# f28p551x_periph_ac_regs register map
Vendor: Texas Instruments
Peripheral module from a debugger description file (folder C2000).
Address unit: 16 bits
Registers are 32-bit, read-write, no defined reset value unless marked. A register's access mark holds for its fields unless they carry their own. Offsets are as the file gives them; lines under a group give offsets from that group; [hi:lo] are bit positions; {n}, {i} and the like mark numbered series; 'fields as' and 'values as' point back to an identical list; <NAME> marks a mode.

## PERIPH_AC_REGS — PERIPH AC Registers
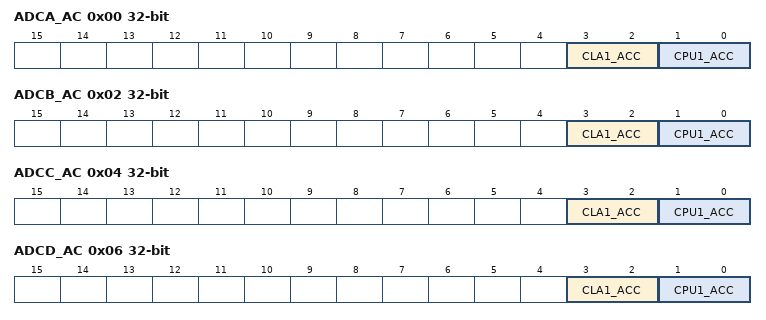
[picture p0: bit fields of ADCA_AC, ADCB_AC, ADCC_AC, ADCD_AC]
0x00 ADCA_AC — ADCA Controller Access Control Register
  [3:2] CLA1_ACC — CLA1 Access Conditions to Peripheral
  [1:0] CPU1_ACC — CPU1 Access conditions to peripheral
0x02 ADCB_AC — ADCB Controller Access Control Register
  fields as ADCA_AC
0x04 ADCC_AC — ADCC Controller Access Control Register
  fields as ADCA_AC
0x06 ADCD_AC — ADCD Controller Access Control Register
  fields as ADCA_AC
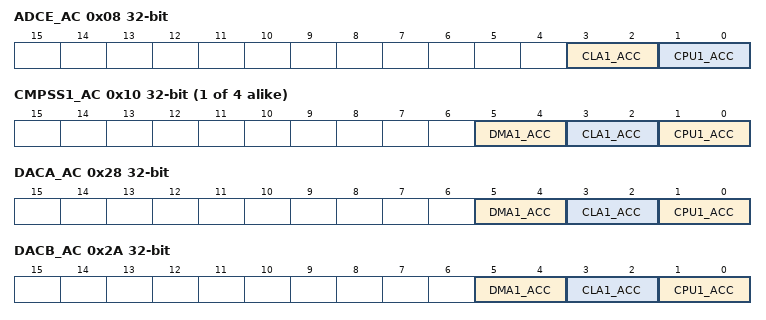
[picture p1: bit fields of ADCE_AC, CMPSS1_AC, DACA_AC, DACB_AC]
0x08 ADCE_AC — ADCE Controller Access Control Register
  fields as ADCA_AC
{0xE+2i} CMPSS{i}_AC (i=1..4) — CMPSS{i} Controller Access Control Register
  [5:4] DMA1_ACC — DMA1 Access Conditions to Peripheral
  [3:2] CLA1_ACC — CLA1 Access Conditions to Peripheral
  [1:0] CPU1_ACC — CPU1 Access conditions to peripheral
0x28 DACA_AC — DACA Controller Access Control Register
  fields as CMPSS1_AC
0x2A DACB_AC — DACB Controller Access Control Register
  fields as CMPSS1_AC
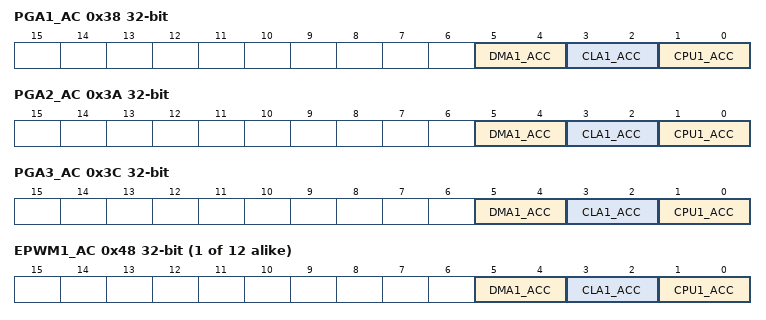
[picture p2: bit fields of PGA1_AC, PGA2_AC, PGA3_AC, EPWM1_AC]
0x38 PGA1_AC — PGAA Controller Access Control Register
  fields as CMPSS1_AC
0x3A PGA2_AC — PGAB Controller Access Control Register
  fields as CMPSS1_AC
0x3C PGA3_AC — PGAC Controller Access Control Register
  fields as CMPSS1_AC
{0x46+2i} EPWM{i}_AC (i=1..12) — EPWM{i} Controller Access Control Register
  fields as CMPSS1_AC
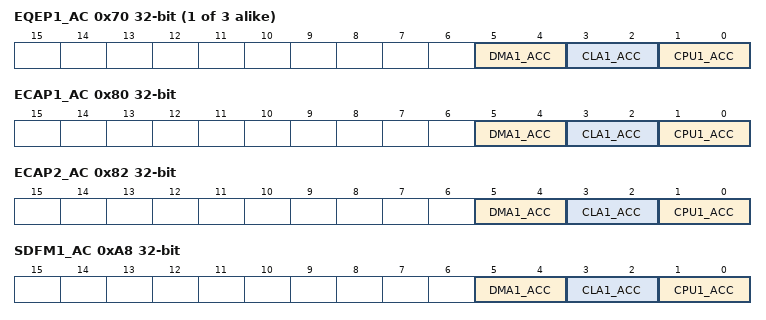
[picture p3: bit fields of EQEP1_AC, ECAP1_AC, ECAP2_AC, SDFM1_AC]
{0x6E+2i} EQEP{i}_AC (i=1..3) — EQEP{i} Controller Access Control Register
  fields as CMPSS1_AC
0x80 ECAP1_AC — ECAP1 Controller Access Control Register
  fields as CMPSS1_AC
0x82 ECAP2_AC — ECAP2 Controller Access Control Register
  fields as CMPSS1_AC
0xA8 SDFM1_AC — SDFM1 Controller Access Control Register
  fields as CMPSS1_AC
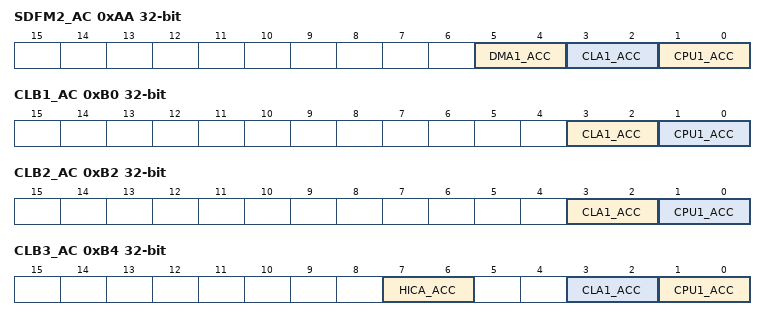
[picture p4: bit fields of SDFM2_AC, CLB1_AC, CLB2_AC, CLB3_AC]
0xAA SDFM2_AC — SDFM2 Controller Access Control Register
  fields as CMPSS1_AC
0xB0 CLB1_AC — CLB1 Controller Access Control Register
  fields as ADCA_AC
0xB2 CLB2_AC — CLB2 Controller Access Control Register
  fields as ADCA_AC
0xB4 CLB3_AC — CLB3 Controller Access Control Register
  [7:6] HICA_ACC — HICA Access Contions to Peripheral
  [3:2] CLA1_ACC — CLA1 Access Conditions to Peripheral
  [1:0] CPU1_ACC — CPU1 Access conditions to peripheral
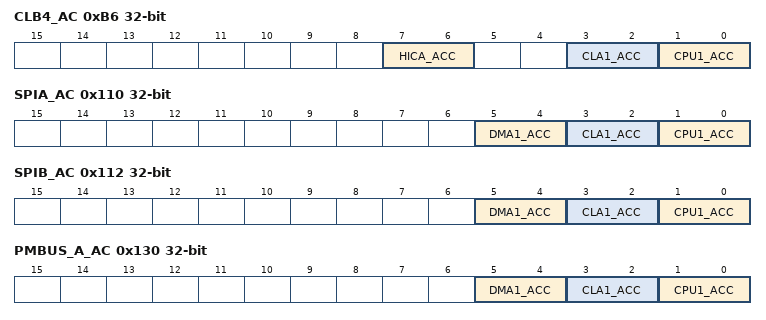
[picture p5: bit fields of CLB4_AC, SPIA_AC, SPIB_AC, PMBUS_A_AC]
0xB6 CLB4_AC — CLB4 Controller Access Control Register
  fields as CLB3_AC
0x100 SCIA_AC — SCIA Controller Access Control Register
  [1:0] CPU1_ACC — CPU1 Access conditions to peripheral
0x102 SCIB_AC — SCIB Controller Access Control Register
  [1:0] CPU1_ACC — CPU1 Access conditions to peripheral
0x104 SCIC_AC — SCIC Controller Access Control Register
  [1:0] CPU1_ACC — CPU1 Access conditions to peripheral
0x110 SPIA_AC — SPIA Controller Access Control Register
  fields as CMPSS1_AC
0x112 SPIB_AC — SPIB Controller Access Control Register
  fields as CMPSS1_AC
0x120 I2CA_AC — I2CA Controller Access Control Register
  [1:0] CPU1_ACC — CPU1 Access conditions to peripheral
0x122 I2CB_AC — I2CB Controller Access Control Register
  [1:0] CPU1_ACC — CPU1 Access conditions to peripheral
0x130 PMBUS_A_AC — PMBUSA Controller Access Control Register
  fields as CMPSS1_AC
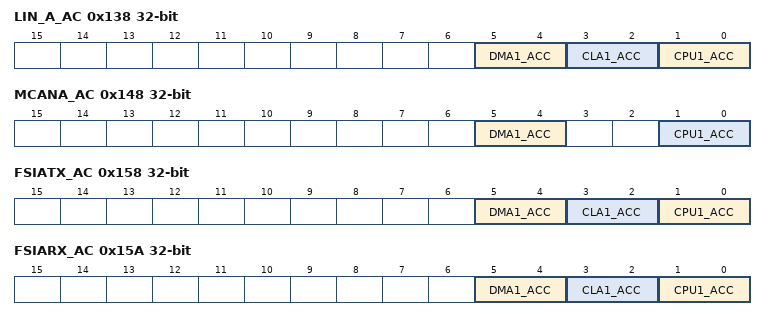
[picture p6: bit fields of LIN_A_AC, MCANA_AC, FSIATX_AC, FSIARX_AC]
0x138 LIN_A_AC — LINA Controller Access Control Register
  fields as CMPSS1_AC
0x148 MCANA_AC — MCANA Controller Access Control Register
  [5:4] DMA1_ACC — DMA1 Access Conditions to Peripheral
  [1:0] CPU1_ACC — CPU1 Access conditions to peripheral
0x158 FSIATX_AC — FSIA Controller Access Control Register
  fields as CMPSS1_AC
0x15A FSIARX_AC — FSIB Controller Access Control Register
  fields as CMPSS1_AC
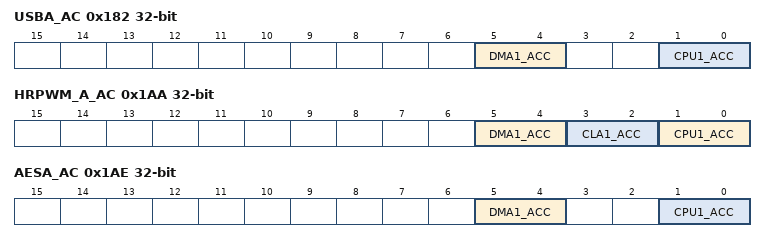
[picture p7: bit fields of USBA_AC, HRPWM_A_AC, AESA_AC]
0x182 USBA_AC — USBA Controller Access Control Register
  fields as MCANA_AC
0x1AA HRPWM_A_AC — HRPWM Controller Access Control Register
  fields as CMPSS1_AC
0x1AE AESA_AC — AES Controller Access Control Register
  fields as MCANA_AC
0x1FE PERIPH_AC_LOCK — Lock Register to stop Write access to peripheral Access register.
  [0] LOCK_AC_WR — Lock control for Access control registers write.
